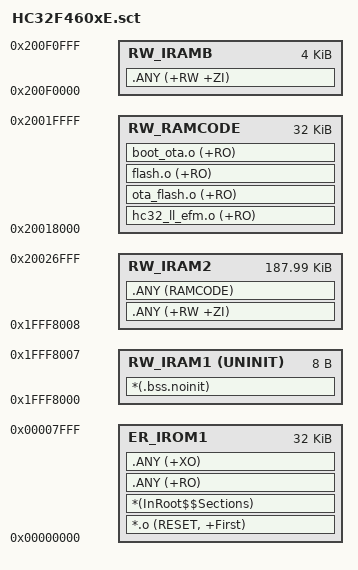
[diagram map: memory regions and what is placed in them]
; ****************************************************************
; HC32F460 报警板 Bootloader 分散加载（Boot 32KB @0x00000000）
; 布局见 docs/ota_boot_design.md v0.2 §3：
;   Boot 0x00000000-0x00007FFF 32KB / 槽A 0x00008000 / 槽B 0x00028000 / 标志 0x0007E000
; 要点：
;   1) ER_IROM1 限死 32KB —— Boot 越界即链接报错，不可能踩到槽区；
;   2) RW_RAMCODE 放【片内 Flash 擦/写期间必须执行的代码】（此时取指不能来自 Flash）：
;        hc32_ll_efm.o  EFM 驱动
;        ota_flash.o    App 同一个擦写模块（全工程一套 OTA 契约）
;        boot_ota.o     引导决策
; ****************************************************************
LR_IROM1 0x00000000 0x00008000  {    ; load region size_region
    ER_IROM1 0x00000000 0x00008000  {  ; load address = execution address
        *.o (RESET, +First)
        *(InRoot$$Sections)
        .ANY (+RO)
        .ANY (+XO)
    }
    RW_IRAM1 0x1FFF8000 UNINIT 0x00000008  {
        *(.bss.noinit)
    }
    RW_IRAM2 0x1FFF8008 0x0002EFF8  {
        .ANY (+RW +ZI)
        .ANY (RAMCODE)
    }
    RW_IRAMB 0x200F0000 0x00001000  {
        .ANY (+RW +ZI)
    }
    RW_RAMCODE 0x20018000 0x00008000  {  ; OTA 擦/写执行区
        hc32_ll_efm.o (+RO)
        ota_flash.o (+RO)
        flash.o (+RO)
        boot_ota.o (+RO)
    }
}
